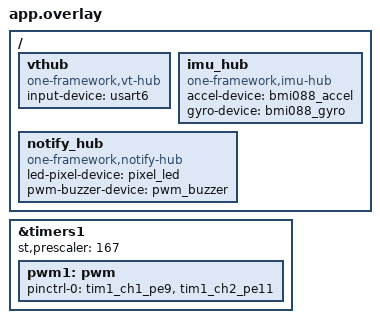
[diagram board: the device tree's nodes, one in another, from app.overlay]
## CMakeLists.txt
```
cmake_minimum_required(VERSION 3.20.0)
find_package(Zephyr REQUIRED HINTS $ENV{ZEPHYR_BASE})
project(one-starter)

target_sources(app PRIVATE src/main.cpp)
```

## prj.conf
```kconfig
CONFIG_ONE_FRAMEWORK=y
CONFIG_NODE=y
CONFIG_LOG=y
CONFIG_ONE_CHASSIS=y
CONFIG_YANDY_GIMBAL=y
CONFIG_YANDY_COMMUNICATE=y

CONFIG_IMU_HUB_REVERSE_AXIS_X=y
CONFIG_IMU_HUB_REVERSE_AXIS_Y=y

CONFIG_SPEED_OPTIMIZATIONS=y
CONFIG_MAIN_STACK_SIZE=8192
CONFIG_OM_DJI_MOTOR_SKIP_N_FRAME=1

CONFIG_IMU_HUB_INIT_CALIBRATION_DURATION_MS=2000
CONFIG_IMU_HUB_GYRO_DEADBAND=30
```

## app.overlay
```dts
/ {
	vthub {
		compatible = "one-framework,vt-hub";
		input-device = <&usart6>;
	};

	imu_hub: imu_hub {
		compatible = "one-framework,imu-hub";
		accel-device = <&bmi088_accel>;
		gyro-device = <&bmi088_gyro>;
	};

	notify_hub {
		compatible = "one-framework,notify-hub";
		led-pixel-device = <&pixel_led>;
		pwm-buzzer-device = <&pwm_buzzer>;
	};
};

&timers1 {
	status = "okay";
	st,prescaler = <167>;

	pwm1: pwm {
		status = "okay";
		pinctrl-0 = <&tim1_ch1_pe9 &tim1_ch2_pe11>;
		pinctrl-names = "default";
	};
};
```

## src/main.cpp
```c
#include <OF/lib/Node/NodeManager.hpp>
#include <zephyr/kernel.h>
#include <zephyr/logging/log.h>

#include "configs.hpp"
#include "RPL/Packets/VT03RemotePacket.hpp"
// #include "OneChassisData.hpp"

// extern Topic<OneChassisData>& topic_one_chassis;
LOG_MODULE_REGISTER(main, CONFIG_LOG_DEFAULT_LEVEL);

#include <OF/lib/VtHub/VtHub.hpp>

using namespace OF;

int main()
{
    LOG_INF("main");
    config_nodes();
    start_all_nodes();
    while (true)
    {
        // const auto data = topic_one_chassis.read();
        // LOG_INF("%s", data.format().c_str());


        const auto res = VtHub::get<VT03RemotePacket>();
        if (!res)
        {
            LOG_WRN("disconnected with vt...");
        }
        k_sleep(K_MSEC(300));
    }
}

//TODO:
// 1. 目前add-node添加的路径还是不对，create-node功能没改 (solved)
// 2. 使用Github模板会把module.yml里的self path带过来，导致所有的目录名都叫one-starter，要不改叫one-app？
```

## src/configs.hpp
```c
#pragma once
#include <OneChassisNode.hpp>
#include <YandyGimbalNode.hpp>
#include <YandyCommunicateNode.hpp>
#include <zephyr/drivers/pwm.h>

// Servo PWM specs - TIM1 CH1 and CH2, 20ms period (50Hz)
// Channel numbering: TIM1_CH1 = 1, TIM1_CH2 = 2
// The PWM device is the pwm child node itself, not its parent (timers)
static constexpr pwm_dt_spec servo1_spec = {
    .dev = DEVICE_DT_GET(DT_NODELABEL(pwm1)),
    .channel = 1,
    .period = PWM_MSEC(20),
    .flags = PWM_POLARITY_NORMAL
};

static constexpr pwm_dt_spec servo2_spec = {
    .dev = DEVICE_DT_GET(DT_NODELABEL(pwm1)),
    .channel = 2,
    .period = PWM_MSEC(20),
    .flags = PWM_POLARITY_NORMAL
};

// 在这里配置 Nodes
void config_nodes()
{
    OneChassisNode::bind<OneChassisNode::Config>({DEVICE_DT_GET(DT_NODELABEL(can2))});

    YandyGimbalNode::bind<YandyGimbalNode::Config>({
        DEVICE_DT_GET(DT_NODELABEL(can1)),
        &servo1_spec,
        &servo2_spec
    });

    YandyCommunicateNode::bind<YandyCommunicateNode::Config>({
        DEVICE_DT_GET(DT_NODELABEL(cdc_acm_uart0))
    });
}
```
